# R7KA8P1AD register map
Vendor: Renesas Electronics Corporation; Series: RA8; File version: 1.10.02
CPU: CM85 r0p2, little endian, MPU, FPU, VTOR, 4 interrupt priority bits, 96 interrupts
Registers are 32-bit, read-write, reset 0x0 unless marked. A register's access mark holds for its fields unless they carry their own. Offsets are from the block's base; [hi:lo] are bit positions; {n}, {i} and the like mark numbered series; 'fields as' and 'values as' point back to an identical list.

## ICU_COMMON — Interrupt Controller
Base 0x40006000
Same registers: ICU_COMMON_NS 0x50006000
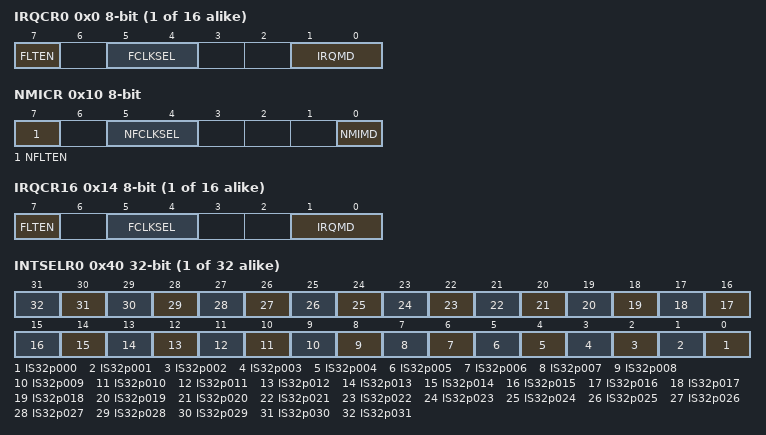
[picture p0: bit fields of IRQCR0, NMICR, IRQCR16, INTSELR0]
{0x0+i} IRQCR{i} 8-bit (i=0..15) — IRQ Control Register
  [7] FLTEN — IRQi Digital Filter Enable
    0=Digital filter is disabled; 1=Digital filter is enabled
  [5:4] FCLKSEL — IRQi Digital Filter Sampling Clock Select
    0=PCLKB; 1=PCLKB/8; 2=PCLKB/32; 3=PCLKB/64
  [1:0] IRQMD — IRQi Detection Sense Select
    0=Falling edge; 1=Rising edge; 2=Rising and falling edges; 3=Low level
0x10 NMICR 8-bit — NMI Pin Interrupt Control Register
  [7] NFLTEN — NMI Digital Filter Enable
    0=Disabled; 1=Enabled
  [5:4] NFCLKSEL — NMI Digital Filter Sampling Clock Select
    0=PCLKB; 1=PCLKB/8; 2=PCLKB/32; 3=PCLKB/64
  [0] NMIMD — NMI Detection Set
    0=Falling edge; 1=Rising edge
{0x4+i} IRQCR{i} 8-bit (i=16..31) — IRQ Control Register
  fields as IRQCR0
{0x40+4i} INTSELR{i} (i=0..31) — Interrupt Request Select Register
  [all] fields
    0=Selected as CPU0 factor; 1=Selected as CPU1 factor
  [n] IS32p{n:03} (n=0..31) — This bit sets whether the interrupt requests and DTC requests are on the CPU0 side or the CPU1 side.

## DMA0 — DMAC Module Contorol
Base 0x4000A800
Same registers: DMA0_NS 0x5000A800
0x00 DMAST 8-bit — DMA Module Activation Register
  [0] DMST — DMAC Operation Enable
    0=DMAC activation is disabled; 1=DMAC activation is enabled
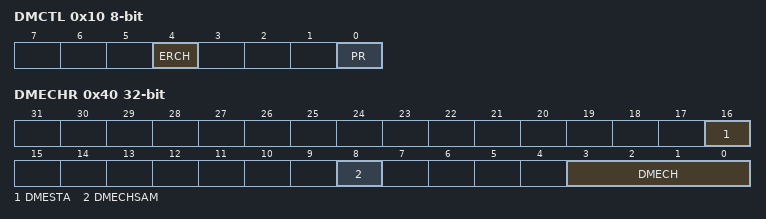
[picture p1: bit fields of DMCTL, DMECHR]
0x10 DMCTL 8-bit — DMAC Control Register
  [4] ERCH — Clear Channel Select
    0=Target channel only; 1=All channels
  [0] PR — Priority Control Select
    0=Fixed priority mode; 1=Round-robin mode
0x40 DMECHR — DMAC Error Channel Register
  [16] DMESTA — DMAC Error Status
    0=No DMA transfer error occurred; 1=DMA transfer error occurred
  [8] DMECHSAM ro — DMAC Error Channel Security Attribution Monitor
    0=secure channel; 1=non-secure channel
  [3:0] DMECH ro — DMAC Error Channel

## DTC0 — Data Transfer Controller
Base 0x4000AC00
0x0C DTCST 8-bit — DTC Module Start Register
  [0] DTCST — DTC Module Start
    0=DTC module stopped; 1=DTC module started
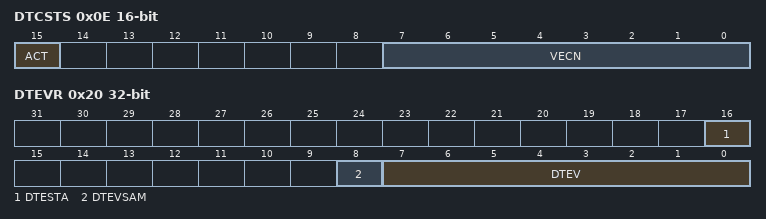
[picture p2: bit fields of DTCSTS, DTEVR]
0x0E DTCSTS 16-bit ro — DTC Status Register
  [15] ACT — DTC Active Flag
    0=DTC transfer operation is not in progress; 1=DTC transfer operation is in progress
  [7:0] VECN — DTC-Activating Vector Number Monitoring
0x10 DTCCR_SEC 8-bit reset 0x8 — DTC Control Register for Secure Region
0x14 DTCVBR_SEC — DTC Vector Base Register for Secure Region
0x18 DTCDISP — DTC Address Displacement Register
  [31:0] DTCDISP — DTC Address Displacement
0x20 DTEVR — DTC Error Vector Register
  [16] DTESTA — DTC Error Status Flag
    0=No DTC transfer error occurred; 1=DTC transfer error occurred
  [8] DTEVSAM ro — DTC Error Vector Number SA Monitor
    0=Secure vector number; 1=Non-secure vector number
  [7:0] DTEV ro — DTC Error Vector Number

## DTC0_NS — Data Transfer Controller for Non-secure
Base 0x5000AC00
Registers as DTC0, without DTCCR_SEC, DTCVBR_SEC; these are added or differ:
0x00 DTCCR 8-bit reset 0x8 — DTC Control Register
  [4] RRS — DTC Transfer Information Read Skip Enable for Non-secure
    0=Transfer information read is not skipped; 1=Transfer information read is skipped when vector numbers match
0x04 DTCVBR — DTC Vector Base Register

## CPU_OCD — OCD Function
Base 0x40011000
Same registers: CPU_OCD_NS 0x50011000
0x00 MCUERRSTAT ro — MCU Error Status Register
  [0] ZERO — Zeroization status flag
    0=Zeroization caused by tamper detection has not been performed; 1=Zeroization caused by tamper detection has been performed
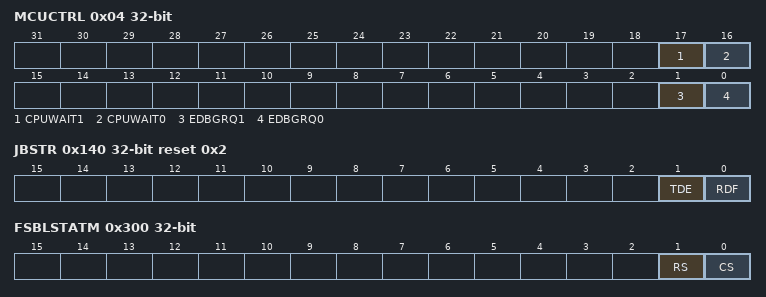
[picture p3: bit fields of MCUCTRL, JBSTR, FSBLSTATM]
0x04 MCUCTRL — MCU Control Register
  [17] CPUWAIT1 — CPU1 WAIT SETTING. Write 1 to assert CPUWAIT1, write 0 to deassert CPUWAIT1.
    0=Clear CPUWAIT1 to low; 1=Set CPUWAIT1 to high
  [16] CPUWAIT0 — CPU0 WAIT SETTING. Write 1 to assert CPUWAIT0, write 0 to deassert CPUWAIT0.
    0=Clear CPUWAIT0 to low; 1=Set CPUWAIT0 to high
  [1] EDBGRQ1 — External Debug Request for CPU1. Writing 1 to the bit causes CPU Halt or Debug Monitor exception request.
    0=Not request debug event; 1=Request debug event
  [0] EDBGRQ0 — External Debug Request for CPU0. Writing 1 to the bit causes CPU Halt or Debug Monitor exception request.
    0=Not request debug event; 1=Request debug event
0x100 JBMDR — JTAG Boot Mode Entry Register
  [7:0] KEY — Mode entry key
0x120 JBRDR — JTAG Boot Receive Data Register
  [31:0] RDAT — Received data register
0x130 JBTDR — JTAG Boot Transmit Data Register
  [31:0] TDAT — Transmitted data register
0x140 JBSTR reset 0x2 — JTAG Boot Status Register
  [1] TDE — Transmit data empty
    0=There is data transmission; 1=No data transmission
  [0] RDF — Receive buffer full
    0=No receiving data; 1=There is receiving data
0x150 JBICR — JTAG Boot Interrupt Control Register
  [0] RDFIE — Receive buffer full interrupt enabled.
    0=Interrupt request disabled by RDF = 1; 1=Enable interrupt request by RDF = 1
0x300 FSBLSTATM ro — First Stage Boot Loader Status Monitor Register
  [1] RS — FSBL result status
    0=FSBL failed; 1=FSBL passed
  [0] CS — FSBL completion status
    0=FSBL is not complete; 1=FSBL is complete
